AUTOSAR XML (schema 00046)
package /Composition_Lab
  sender receiver interface SR1
    data Data: type=uint16, init-value=12
  sensor actuator sw component type SWC1_LightStatus
    provide port SWC1_Provided_Port: provided-interface=SR1
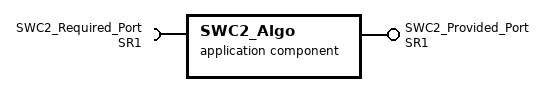
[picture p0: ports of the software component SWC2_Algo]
  application sw component type SWC2_Algo
    require port SWC2_Required_Port: required-interface=SR1
    provide port SWC2_Provided_Port: provided-interface=SR1
  sensor actuator sw component type SWC3_LightControl
    require port SWC3_Required_Port: required-interface=SR1
  composition sw component type Composite1
    provide port Comp1_Provided_Port: provided-interface=SR1
    component SWC1AtComp1: type=SWC1_LightStatus
    component SWC2AtComp1: type=SWC2_Algo
    connect SWC1AtComp1.SWC1_Provided_Port -> SWC2AtComp1.SWC2_Required_Port
    delegate SWC2_Provided_Port <-> outer port Comp1_Provided_Port
  composition sw component type RootComposite
    component Composite1AtRootComp: type=Composite1
    component SWC3AtRootComp: type=SWC3_LightControl
    connect Composite1AtRootComp.Comp1_Provided_Port -> SWC3AtRootComp.SWC3_Required_Port
